AUTOSAR XML (schema 4-2-1)
package /ComponentTypes
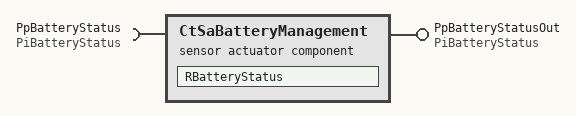
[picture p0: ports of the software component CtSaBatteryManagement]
  sensor actuator sw component type CtSaBatteryManagement
    provide port PpBatteryStatusOut: nonqueued-sender-com-spec{data-element=DeBatteryStatus, init-value=constant-reference=CBatteryStatus}, provided-interface=PiBatteryStatus
    require port PpBatteryStatus: nonqueued-receiver-com-spec{data-element=DeBatteryStatus, filter=data-filter-type=ALWAYS}, required-interface=PiBatteryStatus
    behavior CtSaBatteryManagement_InternalBehavior: data-type-mapping=ApMappingSet
      data received event DRT_RBatteryStatus_PpBatteryStatus_DeBatteryStatus: start-on-event=RBatteryStatus, data=PpBatteryStatus.DeBatteryStatus
      runnable RBatteryStatus
        data-receive-point-by-arguments:
          access REC_PpBatteryStatus_DeBatteryStatus: accessed-variable=PpBatteryStatus.DeBatteryStatus
        data-send-points:
          access SEND_PpBatteryStatusOut_DeBatteryStatus: accessed-variable=PpBatteryStatusOut.DeBatteryStatus
  swc implementation CtSaBatteryManagement_Implementation: behavior=CtSaBatteryManagement_InternalBehavior
    code-descriptors:
      code Default: artifact-descriptors=autosar-engineering-object={short-label=Default, category=SWSRC}
